# I3C0_WRAP_CORE_VBP_MST register map
Vendor: Texas Instruments
Registers are 32-bit, read-write, reset 0x0 unless marked. A register's access mark holds for its fields unless they carry their own. Offsets are as the file gives them; [hi:lo] are bit positions; {n}, {i} and the like mark numbered series; 'fields as' and 'values as' point back to an identical list.

## I3C0_WRAP_CORE_VBP_MST (part 2 of 2)
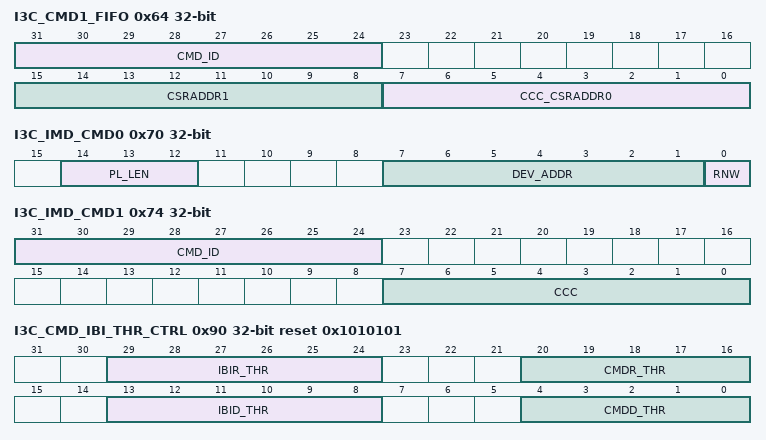
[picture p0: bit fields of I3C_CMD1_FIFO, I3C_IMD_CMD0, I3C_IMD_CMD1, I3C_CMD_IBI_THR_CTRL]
0x64 I3C_CMD1_FIFO access per field — Command 1 FIFO. When implemented, the commands will be executed sequentially in order of arrival from the FW.
  [31:24] CMD_ID wo — COMMAND ID - generated by the host and used by the DMA to sort incoming read data to different consumers [channelization]
  [15:8] CSRADDR1 wo — CSR ADDR 1 - second byte of the CSR address in 16-bit addressing mode Applicable only when 16-bit addressing mode is used and for private commands [non CCC commands]
  [7:0] CCC_CSRADDR0 wo — CCC/CSR ADDR 0 - CCC or CSR Address Meaning of this field depends on bit 30 [IsCCC] of Command Word 0 - When IsCCC is set to '0' then this field holds address of slave CSR When 16-bit addressing is used, then it is the first byte of the CSR address - When IsCCC is set to '1' then this field holds code of CCC
0x68 I3C_TX_FIFO wo — Tx Data FIFO which stores number of bytes to be sent with particular command. APB->I3C direction
  [31:0] DATA — Tx Data FIFO which stores number of bytes to be sent with particular command
0x70 I3C_IMD_CMD0 wo — High priority command register. When the core currently is executing a particular command from the CMD FIFO and new immediate command is sent, the core finish the standard command and then will execute the immediate command, disregarding the CMD FIFO state. Supposed to be used mainly for CCC commands with payload up to 4 bytes.
  [14:12] PL_LEN — PL_LEN - Payload Length The number of bytes to be sent for particular CCC Supports up to 4 bytes
  [7:1] DEV_ADDR — DEV_ADDR - Static/Dynamic slave Address Correspond to a given slave Dynamic Address and Static Address For CCC is applicable only when it is direct CCC command For broadcast CCC this field is ignored
  [0] RNW — RnW - Read no Write Defines the direction of transfer, for broadcast CCC this field is ignored 0 - Write Transfer 1 - Read Transfer
0x74 I3C_IMD_CMD1 access per field — High priority command register. When the core currently is executing a particular command from the CMD FIFO and new immediate command is sent, the core finish the standard command and then will execute the immediate command, disregarding the CMD FIFO state. Supposed to be used mainly for CCC commands with payload up to 4 bytes.
  [31:24] CMD_ID wo — COMMAND ID - generated by the host and used by the DMA to sort incoming read data to different consumers [channelization]
  [7:0] CCC wo — CCC code
0x78 I3C_IMD_DATA — Payload/Data for a particular immediate command.
  [31:0] DATA — Payload/Data for a particular immediate command Supports up to 4 bytes
0x80 I3C_RX_FIFO ro — Rx Data FIFO which stores number of bytes to be received with particular command. I3C->APB direction
  [31:0] DATA — Rx Data FIFO which stores number of bytes to be received with particular command
0x84 I3C_IBI_DATA_FIFO ro — IBI Data FIFO which stores number of bytes to be received for particular IBI request when BCR[2]=1 I3C->APB direction
  [31:0] DATA — IBI Data FIFO which stores number of bytes to be received for particular IBI request
0x88 I3C_SLV_DDR_TX_FIFO wo — DDR Tx Data FIFO stores number of words to be sent with particular DDR command in slave mode. APB->I3C direction
  [19:0] DDR_SLAVE_TX_DATA_FIFO — DDR Tx Data FIFO stores number of words to be sent with particular DDR command in slave mode
0x8C I3C_SLV_DDR_RX_FIFO ro — DDR Rx Data FIFO stores number of words to be received with particular DDR command in slave mode. APB->I3C direction
  [19:0] DDR_SLAVE_RX_DATA_FIFO — DDR Rx Data FIFO stores number of words to be received with particular DDR command in slave mode
0x90 I3C_CMD_IBI_THR_CTRL access per field reset 0x1010101 — Configuration register for Command and In-Band Interrupt data buffer thresholds.
  [29:24] IBIR_THR rw — Threshold configuration value for IBI RESP memory block
  [20:16] CMDR_THR rw — Threshold configuration value for Command RESP memory block
  [13:8] IBID_THR rw — Threshold configuration value for IBI DATA memory block
  [4:0] CMDD_THR rw — Threshold configuration value for Command REQ memory block
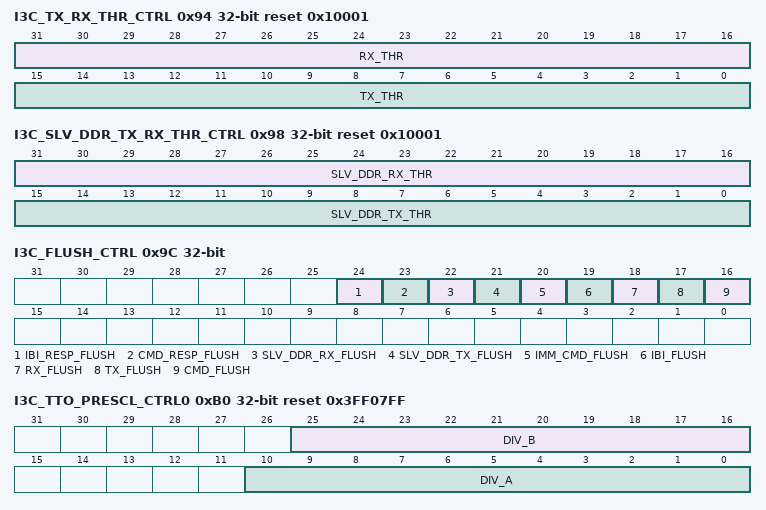
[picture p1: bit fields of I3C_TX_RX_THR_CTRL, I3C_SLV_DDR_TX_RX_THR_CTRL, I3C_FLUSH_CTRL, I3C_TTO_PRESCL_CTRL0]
0x94 I3C_TX_RX_THR_CTRL reset 0x10001 — Configuration register for Tx and Rx data buffer thresholds.
  [31:16] RX_THR — Threshold configuration value for Rx Data memory block
  [15:0] TX_THR — Threshold configuration value for Tx Data memory block
0x98 I3C_SLV_DDR_TX_RX_THR_CTRL reset 0x10001 — Configuration register for Tx and Rx thresholds associated with Slave Mode DDR Data memory blocks.
  [31:16] SLV_DDR_RX_THR — Threshold configuration value for Slave Mode DDR Rx Data memory block
  [15:0] SLV_DDR_TX_THR — Threshold configuration value for Slave Mode DDR Tx Data memory block
0x9C I3C_FLUSH_CTRL wo — Control register for FIFO soft flush control
  [24] IBI_RESP_FLUSH — When asserted while controller is disabled, the IBI Response Queue read/write pointers will be set to 0, effectively make the FIFO empty Self-cleared control bit
  [23] CMD_RESP_FLUSH — When asserted while controller is disabled, the Command Response Queue read/write pointers will be set to 0, effectively make the FIFO empty Self-cleared control bit
  [22] SLV_DDR_RX_FLUSH — When asserted while controller is disabled, the SLV DDR Rx Data memory block read/write pointers will be set to 0, effectively make the FIFO empty Self-cleared control bit
  [21] SLV_DDR_TX_FLUSH — When asserted while controller is disabled, the SLV DDR Tx Data memory block read/write pointers will be set to 0, effectively make the FIFO empty Self-cleared control bit
  [20] IMM_CMD_FLUSH — When asserted while controller is disabled, the immediate command/data register will be cleared Self-cleared control bit
  [19] IBI_FLUSH — When asserted while controller is disabled, the IBI data memory block read/write pointers will be set to 0 Self-cleared control bit
  [18] RX_FLUSH — When asserted while controller is disabled, the Rx Data memory block read/write pointers will be set to 0 Self-cleared control bit
  [17] TX_FLUSH — When asserted while controller is disabled, the Tx Data memory block read/write pointers will be set to 0 Self-cleared control bit
  [16] CMD_FLUSH — When asserted while controller is disabled, the command Command memory block read/write pointers will be set to 0 Self-cleared control bit
0xB0 I3C_TTO_PRESCL_CTRL0 access per field reset 0x3FF07FF — Prescale settings for First SCL high timeout detection
  [25:16] DIV_B rw — Divider B
  [10:0] DIV_A rw — Divider A
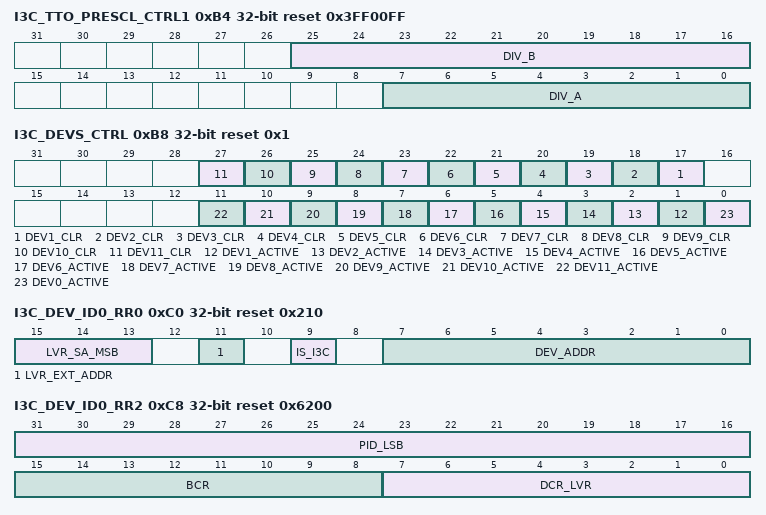
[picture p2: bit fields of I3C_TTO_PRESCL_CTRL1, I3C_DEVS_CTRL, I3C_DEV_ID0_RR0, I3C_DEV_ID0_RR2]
0xB4 I3C_TTO_PRESCL_CTRL1 access per field reset 0x3FF00FF — Prescale settings for SCL high and low timeout detection
  [25:16] DIV_B rw — Divider B
  [7:0] DIV_A rw — Divider A
0xB8 I3C_DEVS_CTRL access per field reset 0x1 — Device control register
  [n+16] DEV{n}_CLR wo (n=1..11) — Clear DevID{n} retaining registers set Self-cleared bit
  [n] DEV{n}_ACTIVE rw (n=1..11) — DevID{n} is active - has either valid DA or SA
  [0] DEV0_ACTIVE ro — DevID0 is active - has either valid DA or SA
0xC0 I3C_DEV_ID0_RR0 access per field reset 0x210 — Device ID 0 Retaining Register 0 : Configuration Register
  [15:13] LVR_SA_MSB rw — MSB bits of Legacy I2C Device with 10-bit addressing
  [11] LVR_EXT_ADDR rw — Device 0 Address mode used: 0 - 7-bit addressing - applicable for I3C and I2C devices 1 - 10-bit addressing - applicable only for I2C devices with 10-bit extended address NOTE: Invalid setting when Device0_RR0is_i3c=1
  [9] IS_I3C ro — Device 0 I3C mode Operation 1 Yes 0 No
  [7:0] DEV_ADDR rw — Device 0 Slave Dynamic [Static/Legacy] Address bits 7:1 bit 0 - parity XOR check -&gt; ~XOR[Slave_Addr [7:1]]
0xC4 I3C_DEV_ID0_RR1 reset 0x2040000 — Device ID 0 Retaining Register 1 : Provisional ID MSB 32-bits
  [31:0] PID_MSB — Device 0 48 to 16 Dev ID bits
0xC8 I3C_DEV_ID0_RR2 reset 0x6200 — Device ID 0 Retaining Register 2 : Provisional ID LSB 16-bits, BCR, DCR or LVR (for legacy Mode)
  [31:16] PID_LSB — Device 0 15 to 0 Dev ID bits
  [15:8] BCR — Device 0 BCR register
  [7:0] DCR_LVR — Device 0 DCR [if I3C device] or LVR [if I2C device] register Decoding if used as DCR: Bits [7:0]: 255 available codes for describing the type of sensor, or Device Decoding if used as LVR: Bits [7:4]: Device 0 LVR Code: 15 available codes for describing the Device capabilities and function on the sensors' system Bits [3:3]: Device 0 LVR Slave operation mode: 1'b0 FM mode 1'b1 FM+ mode Bits [2:0]: Device 0 LVR Index: 3'b000 Index 0 3'b001 Index 1 3'b010 Index 2 3'b011 Index 3 [Reserved] 3'b100 Index 4 [Reserved] 3'b101 Index 5 [Reserved] 3'b110 Index 6 [Reserved] 3'b111 Index 7 [Reserved]
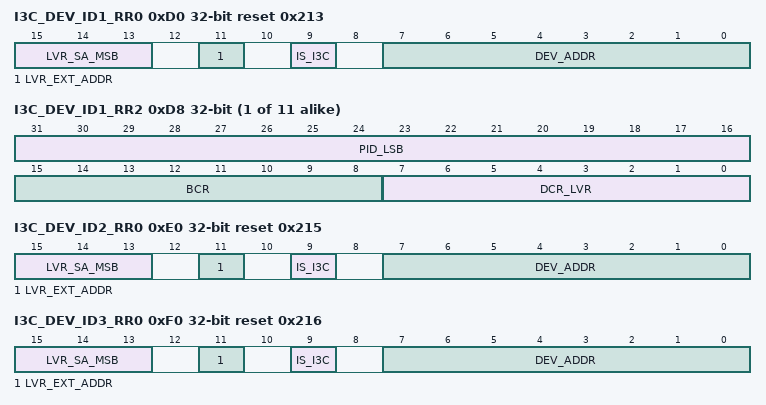
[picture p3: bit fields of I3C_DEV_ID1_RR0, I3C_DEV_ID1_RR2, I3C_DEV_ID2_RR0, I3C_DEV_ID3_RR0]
0xD0 I3C_DEV_ID1_RR0 access per field reset 0x213 — Device ID 1 Retaining Register 0 : Configuration Register
  [15:13] LVR_SA_MSB rw — MSB bits of Legacy I2C Device with 10-bit addressing
  [11] LVR_EXT_ADDR rw — Device 1 Address mode used: 0 - 7-bit addressing - applicable for I3C and I2C devices 1 - 10-bit addressing - applicable only for I2C devices with 10-bit extended address NOTE: Invalid setting when Device1_RR0is_i3c=1
  [9] IS_I3C rw — Device 1 I3C mode Operation 1 Yes 0 No
  [7:0] DEV_ADDR rw — Device 1 Slave Dynamic [Static/Legacy] Address bits 7:1 bit 0 - parity XOR check -&gt; ~XOR[Slave_Addr [7:1]]
{0xC4+0x10*i} I3C_DEV_ID{i}_RR1 (i=1..11) — Device ID {i} Retaining Register 1 : Provisional ID MSB 32-bits
  [31:0] PID_MSB — Device {i} 48 to 16 Dev ID bits
{0xC8+0x10*i} I3C_DEV_ID{i}_RR2 (i=1..11) — Device ID {i} Retaining Register 2 : Provisional ID LSB 16-bits, BCR, DCR or LVR (for legacy Mode)
  [31:16] PID_LSB — Device {i} 15 to 0 Dev ID bits
  [15:8] BCR — Device {i} BCR register
  [7:0] DCR_LVR — Device {i} DCR [if I3C device] or LVR [if I2C device] register Decoding if used as DCR: Bits [7:0]: 255 available codes for describing the type of sensor, or Device Decoding if used as LVR: Bits [7:4]: Device {i} LVR Code: 15 available codes for describing the Device capabilities and function on the sensors' system Bits [3:3]: Device {i} LVR Slave operation mode: 1'b0 FM mode 1'b1 FM+ mode Bits [2:0]: Device {i} LVR Index: 3'b000 Index 0 3'b001 Index 1 3'b010 Index 2 3'b011 Index 3 [Reserved] 3'b100 Index 4 [Reserved] 3'b101 Index 5 [Reserved] 3'b110 Index 6 [Reserved] 3'b111 Index 7 [Reserved]
0xE0 I3C_DEV_ID2_RR0 access per field reset 0x215 — Device ID 2 Retaining Register 0 : Configuration Register
  [15:13] LVR_SA_MSB rw — MSB bits of Legacy I2C Device with 10-bit addressing
  [11] LVR_EXT_ADDR rw — Device 2 Address mode used: 0 - 7-bit addressing - applicable for I3C and I2C devices 1 - 10-bit addressing - applicable only for I2C devices with 10-bit extended address NOTE: Invalid setting when Device2_RR0is_i3c=1
  [9] IS_I3C rw — Device 2 I3C mode Operation 1 Yes 0 No
  [7:0] DEV_ADDR rw — Device 2 Slave Dynamic [Static/Legacy] Address bits 7:1 bit 0 - parity XOR check -&gt; ~XOR[Slave_Addr [7:1]]
0xF0 I3C_DEV_ID3_RR0 access per field reset 0x216 — Device ID 3 Retaining Register 0 : Configuration Register
  [15:13] LVR_SA_MSB rw — MSB bits of Legacy I2C Device with 10-bit addressing
  [11] LVR_EXT_ADDR rw — Device 3 Address mode used: 0 - 7-bit addressing - applicable for I3C and I2C devices 1 - 10-bit addressing - applicable only for I2C devices with 10-bit extended address NOTE: Invalid setting when Device3_RR0is_i3c=1
  [9] IS_I3C rw — Device 3 I3C mode Operation 1 Yes 0 No
  [7:0] DEV_ADDR rw — Device 3 Slave Dynamic [Static/Legacy] Address bits 7:1 bit 0 - parity XOR check -&gt; ~XOR[Slave_Addr [7:1]]
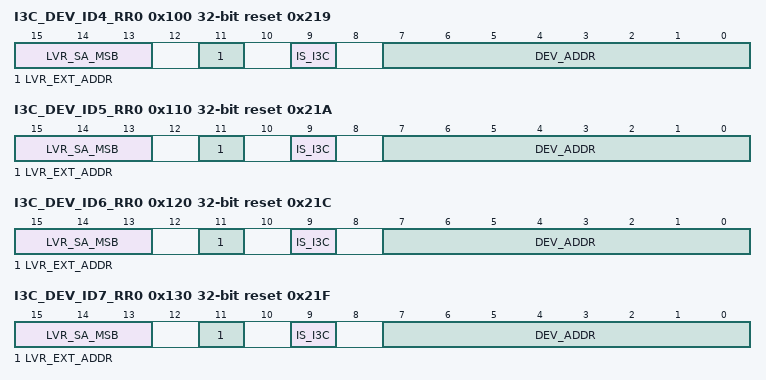
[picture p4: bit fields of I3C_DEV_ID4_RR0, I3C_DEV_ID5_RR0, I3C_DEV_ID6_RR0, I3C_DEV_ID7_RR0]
0x100 I3C_DEV_ID4_RR0 access per field reset 0x219 — Device ID 4 Retaining Register 0 : Configuration Register
  [15:13] LVR_SA_MSB rw — MSB bits of Legacy I2C Device with 10-bit addressing
  [11] LVR_EXT_ADDR rw — Device 4 Address mode used: 0 - 7-bit addressing - applicable for I3C and I2C devices 1 - 10-bit addressing - applicable only for I2C devices with 10-bit extended address NOTE: Invalid setting when Device4_RR0is_i3c=1
  [9] IS_I3C rw — Device 4 I3C mode Operation 1 Yes 0 No
  [7:0] DEV_ADDR rw — Device 4 Slave Dynamic [Static/Legacy] Address bits 7:1 bit 0 - parity XOR check -&gt; ~XOR[Slave_Addr [7:1]]
0x110 I3C_DEV_ID5_RR0 access per field reset 0x21A — Device ID 5 Retaining Register 0 : Configuration Register
  [15:13] LVR_SA_MSB rw — MSB bits of Legacy I2C Device with 10-bit addressing
  [11] LVR_EXT_ADDR rw — Device 5 Address mode used: 0 - 7-bit addressing - applicable for I3C and I2C devices 1 - 10-bit addressing - applicable only for I2C devices with 10-bit extended address NOTE: Invalid setting when Device5_RR0is_i3c=1
  [9] IS_I3C rw — Device 5 I3C mode Operation 1 Yes 0 No
  [7:0] DEV_ADDR rw — Device 5 Slave Dynamic [Static/Legacy] Address bits 7:1 bit 0 - parity XOR check -&gt; ~XOR[Slave_Addr [7:1]]
0x120 I3C_DEV_ID6_RR0 access per field reset 0x21C — Device ID 6 Retaining Register 0 : Configuration Register
  [15:13] LVR_SA_MSB rw — MSB bits of Legacy I2C Device with 10-bit addressing
  [11] LVR_EXT_ADDR rw — Device 6 Address mode used: 0 - 7-bit addressing - applicable for I3C and I2C devices 1 - 10-bit addressing - applicable only for I2C devices with 10-bit extended address NOTE: Invalid setting when Device6_RR0is_i3c=1
  [9] IS_I3C rw — Device 6 I3C mode Operation 1 Yes 0 No
  [7:0] DEV_ADDR rw — Device 6 Slave Dynamic [Static/Legacy] Address bits 7:1 bit 0 - parity XOR check -&gt; ~XOR[Slave_Addr [7:1]]
0x130 I3C_DEV_ID7_RR0 access per field reset 0x21F — Device ID 7 Retaining Register 0 : Configuration Register
  [15:13] LVR_SA_MSB rw — MSB bits of Legacy I2C Device with 10-bit addressing
  [11] LVR_EXT_ADDR rw — Device 7 Address mode used: 0 - 7-bit addressing - applicable for I3C and I2C devices 1 - 10-bit addressing - applicable only for I2C devices with 10-bit extended address NOTE: Invalid setting when Device7_RR0is_i3c=1
  [9] IS_I3C rw — Device 7 I3C mode Operation 1 Yes 0 No
  [7:0] DEV_ADDR rw — Device 7 Slave Dynamic [Static/Legacy] Address bits 7:1 bit 0 - parity XOR check -&gt; ~XOR[Slave_Addr [7:1]]
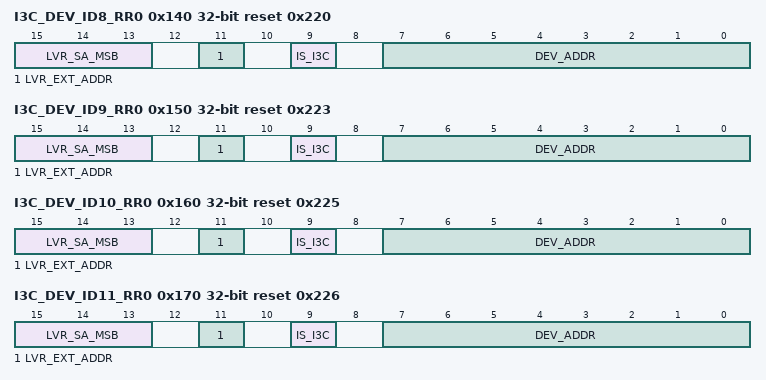
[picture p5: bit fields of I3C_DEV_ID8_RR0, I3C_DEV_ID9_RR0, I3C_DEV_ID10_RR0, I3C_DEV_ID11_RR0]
0x140 I3C_DEV_ID8_RR0 access per field reset 0x220 — Device ID 8 Retaining Register 0 : Configuration Register
  [15:13] LVR_SA_MSB rw — MSB bits of Legacy I2C Device with 10-bit addressing
  [11] LVR_EXT_ADDR rw — Device 8 Address mode used: 0 - 7-bit addressing - applicable for I3C and I2C devices 1 - 10-bit addressing - applicable only for I2C devices with 10-bit extended address NOTE: Invalid setting when Device8_RR0is_i3c=1
  [9] IS_I3C rw — Device 8 I3C mode Operation 1 Yes 0 No
  [7:0] DEV_ADDR rw — Device 8 Slave Dynamic [Static/Legacy] Address bits 7:1 bit 0 - parity XOR check -&gt; ~XOR[Slave_Addr [7:1]]
0x150 I3C_DEV_ID9_RR0 access per field reset 0x223 — Device ID 9 Retaining Register 0 : Configuration Register
  [15:13] LVR_SA_MSB rw — MSB bits of Legacy I2C Device with 10-bit addressing
  [11] LVR_EXT_ADDR rw — Device 9 Address mode used: 0 - 7-bit addressing - applicable for I3C and I2C devices 1 - 10-bit addressing - applicable only for I2C devices with 10-bit extended address NOTE: Invalid setting when Device9_RR0is_i3c=1
  [9] IS_I3C rw — Device 9 I3C mode Operation 1 Yes 0 No
  [7:0] DEV_ADDR rw — Device 9 Slave Dynamic [Static/Legacy] Address bits 7:1 bit 0 - parity XOR check -&gt; ~XOR[Slave_Addr [7:1]]
0x160 I3C_DEV_ID10_RR0 access per field reset 0x225 — Device ID 10 Retaining Register 0 : Configuration Register
  [15:13] LVR_SA_MSB rw — MSB bits of Legacy I2C Device with 10-bit addressing
  [11] LVR_EXT_ADDR rw — Device 10 Address mode used: 0 - 7-bit addressing - applicable for I3C and I2C devices 1 - 10-bit addressing - applicable only for I2C devices with 10-bit extended address NOTE: Invalid setting when Device10_RR0is_i3c=1
  [9] IS_I3C rw — Device 10 I3C mode Operation 1 Yes 0 No
  [7:0] DEV_ADDR rw — Device 10 Slave Dynamic [Static/Legacy] Address bits 7:1 bit 0 - parity XOR check -&gt; ~XOR[Slave_Addr [7:1]]
0x170 I3C_DEV_ID11_RR0 access per field reset 0x226 — Device ID 11 Retaining Register 0 : Configuration Register
  [15:13] LVR_SA_MSB rw — MSB bits of Legacy I2C Device with 10-bit addressing
  [11] LVR_EXT_ADDR rw — Device 11 Address mode used: 0 - 7-bit addressing - applicable for I3C and I2C devices 1 - 10-bit addressing - applicable only for I2C devices with 10-bit extended address NOTE: Invalid setting when Device11_RR0is_i3c=1
  [9] IS_I3C rw — Device 11 I3C mode Operation 1 Yes 0 No
  [7:0] DEV_ADDR rw — Device 11 Slave Dynamic [Static/Legacy] Address bits 7:1 bit 0 - parity XOR check -&gt; ~XOR[Slave_Addr [7:1]]
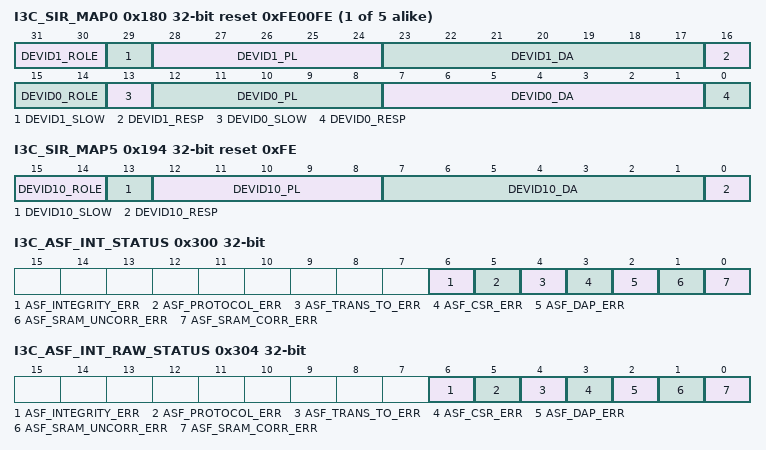
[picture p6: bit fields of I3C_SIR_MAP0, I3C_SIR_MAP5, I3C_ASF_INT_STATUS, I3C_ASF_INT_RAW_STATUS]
{0x180+4i} I3C_SIR_MAP{i} reset 0xFE00FE (i=0..4) — Slave-initiated request Device ID Detection register{i}
  [31:30] DEVID{2i+1}_ROLE — Slave-initiated request Device ID{2i} BCR role 2'b 00 - Slave 2'b 01 - Master/Secondary Master 2'b 10 - Reserved 2'b 11 - Reserved
  [29] DEVID{2i+1}_SLOW — Slave-initiated request Device ID{2i} Max Data Speed Limitation 0 - No limitation 1 - Limitation
  [28:24] DEVID{2i+1}_PL — Slave-initiated request Device ID{2i} payload length
  [23:17] DEVID{2i+1}_DA — Slave-initiated request Device ID{2i} DA
  [16] DEVID{2i+1}_RESP — Slave-initiated request Device ID{2i} Ack/Nack response 0 - NACK each request from this device 1 - ACK each request from this device
  [15:14] DEVID{2i}_ROLE — Slave-initiated request Device ID{2i} BCR role 2'b 00 - Slave 2'b 01 - Master/Secondary Master 2'b 10 - Reserved 2'b 11 - Reserved
  [13] DEVID{2i}_SLOW — Slave-initiated request Device ID{2i} Max Data Speed Limitation 0 - No limitation 1 - Limitation
  [12:8] DEVID{2i}_PL — Slave-initiated request Device ID{2i} payload length
  [7:1] DEVID{2i}_DA — Slave-initiated request Device ID{2i} DA
  [0] DEVID{2i}_RESP — Slave-initiated request Device ID{2i} Ack/Nack response 0 - NACK each request from this device 1 - ACK each request from this device
0x194 I3C_SIR_MAP5 reset 0xFE — Slave-initiated request Device ID Detection register5
  [15:14] DEVID10_ROLE — Slave-initiated request Device ID10 BCR role 2'b 00 - Slave 2'b 01 - Master/Secondary Master 2'b 10 - Reserved 2'b 11 - Reserved
  [13] DEVID10_SLOW — Slave-initiated request Device ID10 Max Data Speed Limitation 0 - No limitation 1 - Limitation
  [12:8] DEVID10_PL — Slave-initiated request Device ID10 payload length
  [7:1] DEVID10_DA — Slave-initiated request Device ID10 DA
  [0] DEVID10_RESP — Slave-initiated request Device ID10 Ack/Nack response 0 - NACK each request from this device 1 - ACK each request from this device
0x1A0 I3C_GPIR_WORD0 ro — User Defined GPI Word 0: four 8-bits GPI Registers
  [7:0] GPI0 — User Defined GPI Register 0
0x220 I3C_GPOR_WORD0 ro — User Defined GPO Word 0: four 8-bits GPO Registers
  [7:0] GPO0 — User Defined GPO Register 0
0x300 I3C_ASF_INT_STATUS access not given — ASF Interrupt Status Register. This register indicates the source of ASF interrupts. The corresponding bit in the mask register must be clear for a bit to be set. If any bit is set in this register the asf_fatal or asf_nonfatal signal will be asserted. Writing to either raw or masked status registers, clear both registers. For test purposes, trigger signal interrupt event by writing to the ASF interrupt status test register.
  [6] ASF_INTEGRITY_ERR — Integrity error interrupt (access RW1C)
  [5] ASF_PROTOCOL_ERR — Protocol error interrupt (access RW1C)
  [4] ASF_TRANS_TO_ERR — Transaction timeouts error interrupt (access RW1C)
  [3] ASF_CSR_ERR — Configuration and status registers error interrupt (access RW1C)
  [2] ASF_DAP_ERR — Data and address paths parity error interrupt (access RW1C)
  [1] ASF_SRAM_UNCORR_ERR — SRAM uncorrectable error interrupt (access RW1C)
  [0] ASF_SRAM_CORR_ERR — SRAM correctable error interrupt (access RW1C)
0x304 I3C_ASF_INT_RAW_STATUS access not given — ASF Interrupt Raw Status Register. A bit set in this raw register indicates a source of ASF fault in the corresponding feature. Writing to either raw or masked status registers, clear both registers. For test purposes, trigger signal interrupt event by writing to the ASF interrupt status test register.
  fields as I3C_ASF_INT_STATUS
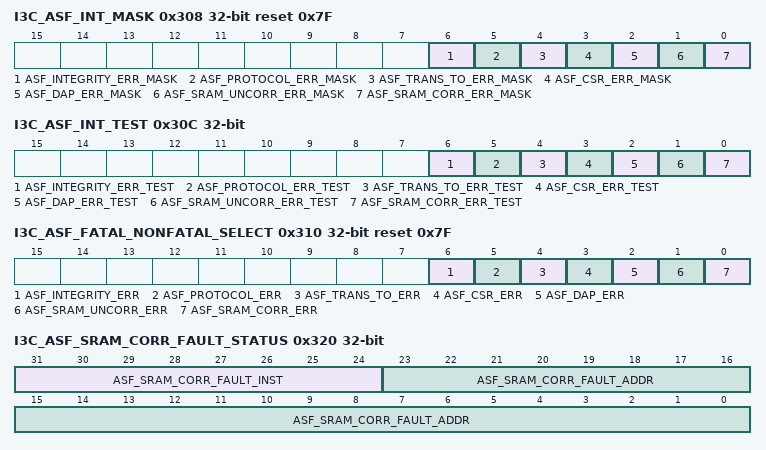
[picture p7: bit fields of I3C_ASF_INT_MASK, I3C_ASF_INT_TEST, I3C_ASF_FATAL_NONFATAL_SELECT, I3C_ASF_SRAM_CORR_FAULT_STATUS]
0x308 I3C_ASF_INT_MASK access per field reset 0x7F — The ASF interrupt mask register indicating which interrupt bits in the ASF interrupt status register are masked. All bits are set at reset. Clear the individual bit to enable the corresponding interrupt.
  [6] ASF_INTEGRITY_ERR_MASK rw — Mask bit for integrity error interrupt
  [5] ASF_PROTOCOL_ERR_MASK rw — Mask bit for protocol error interrupt
  [4] ASF_TRANS_TO_ERR_MASK rw — Mask bit for transaction timeouts error interrupt
  [3] ASF_CSR_ERR_MASK rw — Mask bit for configuration and status registers error interrupt
  [2] ASF_DAP_ERR_MASK rw — Mask bit for data and address paths parity error interrupt
  [1] ASF_SRAM_UNCORR_ERR_MASK rw — Mask bit for SRAM uncorrectable error interrupt
  [0] ASF_SRAM_CORR_ERR_MASK rw — Mask bit for SRAM correctable error interrupt
0x30C I3C_ASF_INT_TEST access per field — The ASF interrupt test register emulate hardware even. Write one to individual bit to trigger single event in (masked and raw) status registers according to mask and will generate interrupt accordingly.
  [6] ASF_INTEGRITY_ERR_TEST wo — Test bit for integrity error interrupt
  [5] ASF_PROTOCOL_ERR_TEST wo — Test bit for protocol error interrupt
  [4] ASF_TRANS_TO_ERR_TEST wo — Test bit for transaction timeouts error interrupt
  [3] ASF_CSR_ERR_TEST wo — Test bit for configuration and status registers error interrupt
  [2] ASF_DAP_ERR_TEST wo — Test bit for data and address paths parity error interrupt
  [1] ASF_SRAM_UNCORR_ERR_TEST wo — Test bit for SRAM uncorrectable error interrupt
  [0] ASF_SRAM_CORR_ERR_TEST wo — Test bit for SRAM correctable error interrupt
0x310 I3C_ASF_FATAL_NONFATAL_SELECT access per field reset 0x7F — The fatal or non-fatal interrupt register selects whether a fatal (asf_int_fatal) or non-fatal (asf_int_nonfatal) interrupt is triggered. If the bit of the event will be set to one then fatal interrupt (asf_int_fatal) will be triggered. Otherwise the non-fatal interrupt (asf_int_nonfatal) will be triggered.
  [6] ASF_INTEGRITY_ERR rw — Enable integrity error interrupt as fatal
  [5] ASF_PROTOCOL_ERR rw — Enable protocol error interrupt as fatal
  [4] ASF_TRANS_TO_ERR rw — Enable transaction timeouts error interrupt as fatal
  [3] ASF_CSR_ERR rw — Enable configuration and status registers error interrupt as fatal
  [2] ASF_DAP_ERR rw — Enable data and address paths parity error interrupt as fatal
  [1] ASF_SRAM_UNCORR_ERR rw — Enable SRAM uncorrectable error interrupt as fatal
  [0] ASF_SRAM_CORR_ERR rw — Enable SRAM correctable error interrupt as fatal
0x320 I3C_ASF_SRAM_CORR_FAULT_STATUS ro — Status register for SRAM correctable fault. These fields are updated whenever asf_sram_corr_fault input is active.
  [31:24] ASF_SRAM_CORR_FAULT_INST — Last SRAM instance that generated fault
  [23:0] ASF_SRAM_CORR_FAULT_ADDR — Last SRAM address that generated fault
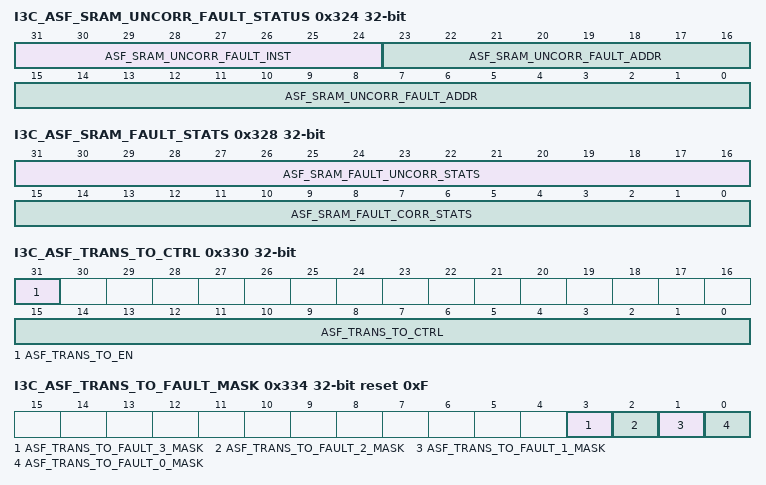
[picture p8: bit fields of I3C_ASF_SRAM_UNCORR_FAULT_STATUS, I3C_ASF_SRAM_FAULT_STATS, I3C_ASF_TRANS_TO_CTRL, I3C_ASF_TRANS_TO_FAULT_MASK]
0x324 I3C_ASF_SRAM_UNCORR_FAULT_STATUS ro — Status register for SRAM uncorrectable fault. These fields are updated whenever asf_sram_uncorr_fault input is active.
  [31:24] ASF_SRAM_UNCORR_FAULT_INST — Last SRAM instance that generated fault
  [23:0] ASF_SRAM_UNCORR_FAULT_ADDR — Last SRAM address that generated fault
0x328 I3C_ASF_SRAM_FAULT_STATS access not given — Statistics register for SRAM faults. Note that this register clears when software writes to any field.
  [31:16] ASF_SRAM_FAULT_UNCORR_STATS — Count of number of uncorrectable errors if implemented Count value will saturate at 0xffff (access RW1C)
  [15:0] ASF_SRAM_FAULT_CORR_STATS — Count of number of correctable errors if implemented Count value will saturate at 0xffff (access RW1C)
0x330 I3C_ASF_TRANS_TO_CTRL access per field — Control register to configure the ASF transaction timeout monitors.
  [31] ASF_TRANS_TO_EN rw — Enable transaction timeout monitoring
  [15:0] ASF_TRANS_TO_CTRL rw — Timer value to use for transaction timeout monitor
0x334 I3C_ASF_TRANS_TO_FAULT_MASK access per field reset 0xF — Control register to mask out ASF transaction timeout faults from triggering interrupts. On reset, all bits are set to mask out all sources. Clear the corresponding bit to enable the interrupt source. The width of this field is parameterizable and the bit definitions are implementation specific.
  [3] ASF_TRANS_TO_FAULT_3_MASK rw — Mask bit for apb transaction timeout fault
  [2] ASF_TRANS_TO_FAULT_2_MASK rw — Mask bit for I3C transaction SCL low timeout fault
  [1] ASF_TRANS_TO_FAULT_1_MASK rw — Mask bit for I3C transaction SCL high timeout fault
  [0] ASF_TRANS_TO_FAULT_0_MASK rw — Mask bit for I3C transaction first SCL high timeout fault
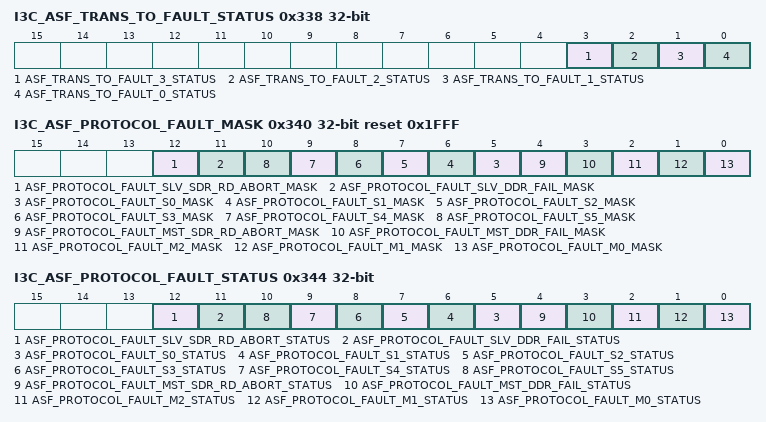
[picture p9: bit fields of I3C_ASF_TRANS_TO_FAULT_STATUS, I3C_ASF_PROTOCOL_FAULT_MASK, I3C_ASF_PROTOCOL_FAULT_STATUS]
0x338 I3C_ASF_TRANS_TO_FAULT_STATUS access not given — Status register for transaction timeouts fault. If a fault occurs the relevant status bit will be set to 1. Each bit can be cleared by software writing 1 to each bit.
  [3] ASF_TRANS_TO_FAULT_3_STATUS — Status bits for apb transaction timeout fault (access RW1C)
  [2] ASF_TRANS_TO_FAULT_2_STATUS — Status bits for I3C transaction SCL low timeout fault (access RW1C)
  [1] ASF_TRANS_TO_FAULT_1_STATUS — Status bits for I3C transaction SCL high timeout fault (access RW1C)
  [0] ASF_TRANS_TO_FAULT_0_STATUS — Status bits for I3C transaction first SCL high timeout fault (access RW1C)
0x340 I3C_ASF_PROTOCOL_FAULT_MASK access per field reset 0x1FFF — Control register to mask out ASF Protocol faults from triggering interrupts. On reset, all bits are set to mask out all sources. Clear the corresponding bit to enable the interrupt source. The width of this field is parameterisable and the bit definitions are implementation specific.
  [12] ASF_PROTOCOL_FAULT_SLV_SDR_RD_ABORT_MASK rw — Mask bit for slv_sdr_rd_abort protocol fault source
  [11] ASF_PROTOCOL_FAULT_SLV_DDR_FAIL_MASK rw — Mask bit for slv_ddr_fail protocol fault source
  [n+5] ASF_PROTOCOL_FAULT_S{n}_MASK rw (n=0..5) — Mask bit for s{n} protocol fault source
  [4] ASF_PROTOCOL_FAULT_MST_SDR_RD_ABORT_MASK rw — Mask bit for mst_sdr_rd_abort protocol fault source
  [3] ASF_PROTOCOL_FAULT_MST_DDR_FAIL_MASK rw — Mask bit for mst_ddr_fail protocol fault source
  [2] ASF_PROTOCOL_FAULT_M2_MASK rw — Mask bit for m2 protocol fault source
  [1] ASF_PROTOCOL_FAULT_M1_MASK rw — Mask bit for m1 protocol fault source
  [0] ASF_PROTOCOL_FAULT_M0_MASK rw — Mask bit for m0 protocol fault source
0x344 I3C_ASF_PROTOCOL_FAULT_STATUS access not given — Status register for protocol faults. If a fault occurs the relevant status bit will be set to 1. Each bit can be cleared by software writing 1 to each bit
  [12] ASF_PROTOCOL_FAULT_SLV_SDR_RD_ABORT_STATUS — Status bit for slv_sdr_rd_abort protocol fault (access RW1C)
  [11] ASF_PROTOCOL_FAULT_SLV_DDR_FAIL_STATUS — Status bit for slv_ddr_fail protocol fault (access RW1C)
  [n+5] ASF_PROTOCOL_FAULT_S{n}_STATUS (n=0..5) — Status bit for s{n} protocol fault (access RW1C)
  [4] ASF_PROTOCOL_FAULT_MST_SDR_RD_ABORT_STATUS — Status bit for mst_sdr_rd_abort protocol fault (access RW1C)
  [3] ASF_PROTOCOL_FAULT_MST_DDR_FAIL_STATUS — Status bit for mst_ddr_fail protocol fault (access RW1C)
  [2] ASF_PROTOCOL_FAULT_M2_STATUS — Status bit for m2 protocol fault (access RW1C)
  [1] ASF_PROTOCOL_FAULT_M1_STATUS — Status bit for m1 protocol fault (access RW1C)
  [0] ASF_PROTOCOL_FAULT_M0_STATUS — Status bit for m0 protocol fault (access RW1C)
